# YC3122 register map
Series: ARMCM0; File version: 1.0
CPU: CM0 r1p0, little endian, no MPU, no FPU, 8 interrupt priority bits
Registers are 32-bit, read-write, reset 0x0 unless marked. A register's access mark holds for its fields unless they carry their own. Offsets are from the block's base; [hi:lo] are bit positions.

## ANA_BBPLL — 32 ANA_BBPLL
Base 0x000FB210
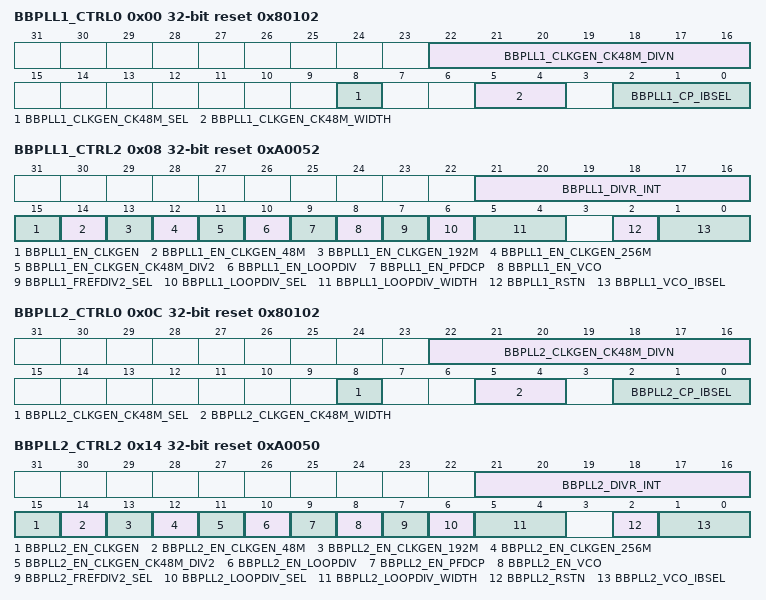
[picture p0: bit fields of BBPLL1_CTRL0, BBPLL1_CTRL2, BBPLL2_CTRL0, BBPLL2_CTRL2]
0x00 BBPLL1_CTRL0 reset 0x80102 — BBPLL1 control
  [22:16] BBPLL1_CLKGEN_CK48M_DIVN — div_ratio of 48MHz
  [8] BBPLL1_CLKGEN_CK48M_SEL — Pulse width select mode enable
  [5:4] BBPLL1_CLKGEN_CK48M_WIDTH — pulse width select
  [2:0] BBPLL1_CP_IBSEL — lcp sel
0x04 BBPLL1_CTRL1 — BBPLL1 control
  [23:0] BBPLL1_DIVR_FRAC — divr of pll
0x08 BBPLL1_CTRL2 reset 0xA0052 — BBPLL1 control
  [21:16] BBPLL1_DIVR_INT — divr of pll
  [15] BBPLL1_EN_CLKGEN — clk_gen enable
  [14] BBPLL1_EN_CLKGEN_48M — 48M clk_gen enable
  [13] BBPLL1_EN_CLKGEN_192M — 192M clk_gen enable
  [12] BBPLL1_EN_CLKGEN_256M — 256M clk_gen enable
  [11] BBPLL1_EN_CLKGEN_CK48M_DIV2 — 48M div2 enable
  [10] BBPLL1_EN_LOOPDIV — loopdivider enable
  [9] BBPLL1_EN_PFDCP — pfd and chargepump enable
  [8] BBPLL1_EN_VCO — VCO enable
  [7] BBPLL1_FREFDIV2_SEL — Reference clk div sel
  [6] BBPLL1_LOOPDIV_SEL — Pulse width select mode enable
  [5:4] BBPLL1_LOOPDIV_WIDTH — Pulse width select
  [2] BBPLL1_RSTN — Reset signal of pll
  [1:0] BBPLL1_VCO_IBSEL — Bias current select of vco
0x0C BBPLL2_CTRL0 reset 0x80102 — BBPLL2 control
  [22:16] BBPLL2_CLKGEN_CK48M_DIVN — div_ratio of 48MHz
  [8] BBPLL2_CLKGEN_CK48M_SEL — Pulse width select mode enable
  [5:4] BBPLL2_CLKGEN_CK48M_WIDTH — pulse width select
  [2:0] BBPLL2_CP_IBSEL — lcp sel
0x10 BBPLL2_CTRL1 — BBPLL2 control
  [23:0] BBPLL2_DIVR_FRAC — divr of pll
0x14 BBPLL2_CTRL2 reset 0xA0050 — BBPLL2 control
  [21:16] BBPLL2_DIVR_INT — divr of pll
  [15] BBPLL2_EN_CLKGEN — clk_gen enable
  [14] BBPLL2_EN_CLKGEN_48M — 48M clk_gen enable
  [13] BBPLL2_EN_CLKGEN_192M — 192M clk_gen enable
  [12] BBPLL2_EN_CLKGEN_256M — 256M clk_gen enable
  [11] BBPLL2_EN_CLKGEN_CK48M_DIV2 — 48M div2 enable
  [10] BBPLL2_EN_LOOPDIV — loopdivider enable
  [9] BBPLL2_EN_PFDCP — pfd and chargepump enable
  [8] BBPLL2_EN_VCO — VCO enable
  [7] BBPLL2_FREFDIV2_SEL — Reference clk div sel
  [6] BBPLL2_LOOPDIV_SEL — Pulse width select mode enable
  [5:4] BBPLL2_LOOPDIV_WIDTH — Pulse width select
  [2] BBPLL2_RSTN — Reset signal of pll
  [1:0] BBPLL2_VCO_IBSEL — Bias current select of vco
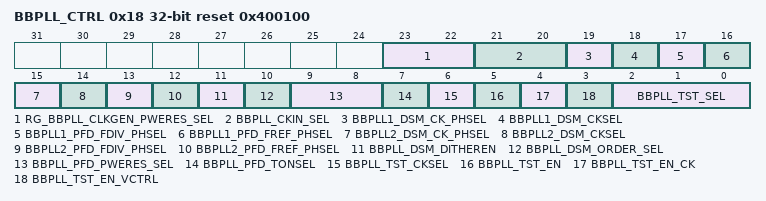
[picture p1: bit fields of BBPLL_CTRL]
0x18 BBPLL_CTRL reset 0x400100 — BBPLL control
  [23:22] RG_BBPLL_CLKGEN_PWERES_SEL — Power Res select
  [21:20] BBPLL_CKIN_SEL — PLL clk input select
  [19] BBPLL1_DSM_CK_PHSEL — DSM clk phase select
  [18] BBPLL1_DSM_CKSEL — DSM clk select
  [17] BBPLL1_PFD_FDIV_PHSEL — fdiv phase select
  [16] BBPLL1_PFD_FREF_PHSEL — fref phase select
  [15] BBPLL2_DSM_CK_PHSEL — DSM clk phase select
  [14] BBPLL2_DSM_CKSEL — DSM clk select
  [13] BBPLL2_PFD_FDIV_PHSEL — fdiv phase select
  [12] BBPLL2_PFD_FREF_PHSEL — fref phase select
  [11] BBPLL_DSM_DITHEREN — DSM dither enable
  [10] BBPLL_DSM_ORDER_SEL — DSM mesh order select
  [9:8] BBPLL_PFD_PWERES_SEL — Power Res select
  [7] BBPLL_PFD_TONSEL — pfd ton select
  [6] BBPLL_TST_CKSEL — clk test select
  [5] BBPLL_TST_EN — pll test enable
  [4] BBPLL_TST_EN_CK — clk test enable
  [3] BBPLL_TST_EN_VCTRL — vctrl test enable
  [2:0] BBPLL_TST_SEL — pll test select

## ANA_MCR — 32 ANA_MCR
Base 0x000FB230
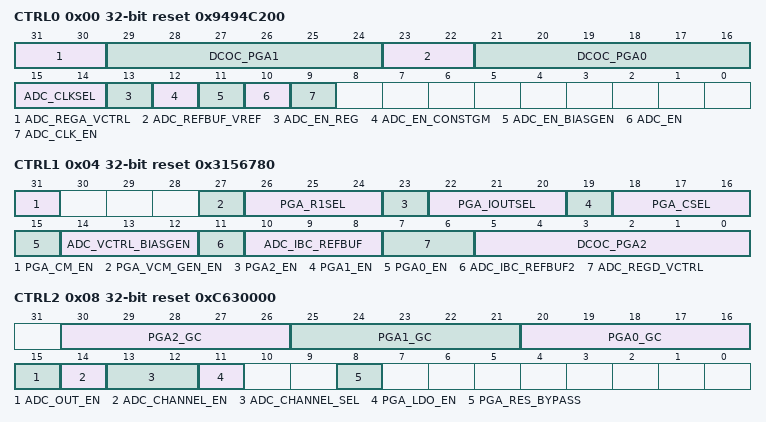
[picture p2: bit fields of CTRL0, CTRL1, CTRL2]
0x00 CTRL0 reset 0x9494C200 — MCR control
  [31:30] ADC_REGA_VCTRL — MCR ADC analog regulator output voltage control
  [29:24] DCOC_PGA1 — MCR CH1 PGA DCOC DAC input
  [23:22] ADC_REFBUF_VREF — MCR ADC differential reference voltage control
  [21:16] DCOC_PGA0 — MCR CH0 PGA DCOC DAC input
  [15:14] ADC_CLKSEL — MCR ADC clock select
  [13] ADC_EN_REG — MCR ADC regulator enable
  [12] ADC_EN_CONSTGM — MCR ADC constant Gm bias enable
  [11] ADC_EN_BIASGEN — MCR ADC reference voltage enable
  [10] ADC_EN — MCR ADC enable
  [9] ADC_CLK_EN — MCR ADC clock enable
0x04 CTRL1 reset 0x3156780 — MCR control
  [31] PGA_CM_EN — MCR PGA input common mode feedback enable
  [27] PGA_VCM_GEN_EN — MCR PGA input common mode buffer enable
  [26:24] PGA_R1SEL — pag input resistor selection
  [23] PGA2_EN — MCR CH2 PGA enable
  [22:20] PGA_IOUTSEL — MCR PAG output current enhance
  [19] PGA1_EN — MCR CH1 PGA enable
  [18:16] PGA_CSEL — MCR lowpass cap selection cap
  [15] PGA0_EN — MCR CH0 PGA enable
  [14:12] ADC_VCTRL_BIASGEN — MCR ADC bias voltage control
  [11] ADC_IBC_REFBUF2 — MCR ADC bias voltage buffer bias current control
  [10:8] ADC_IBC_REFBUF — MCR ADC differential reference voltage buffer bias current control
  [7:6] ADC_REGD_VCTRL — MCR ADC digital regulator output voltage control
  [5:0] DCOC_PGA2 — MCR CH2 PGA DCOC DAC input
0x08 CTRL2 reset 0xC630000 — MCR control
  [30:26] PGA2_GC — MCR CH2 PGA gain control
  [25:21] PGA1_GC — MCR CH1 PGA gain control
  [20:16] PGA0_GC — MCR CH0 PGA gain control
  [15] ADC_OUT_EN — MCR adc input connect to test pad enable
  [14] ADC_CHANNEL_EN — mcr adc test channel enable
  [13:12] ADC_CHANNEL_SEL — mcr adc test channel sel
  [11] PGA_LDO_EN — MCR PGA LDO enable
  [8] PGA_RES_BYPASS — MCR control
